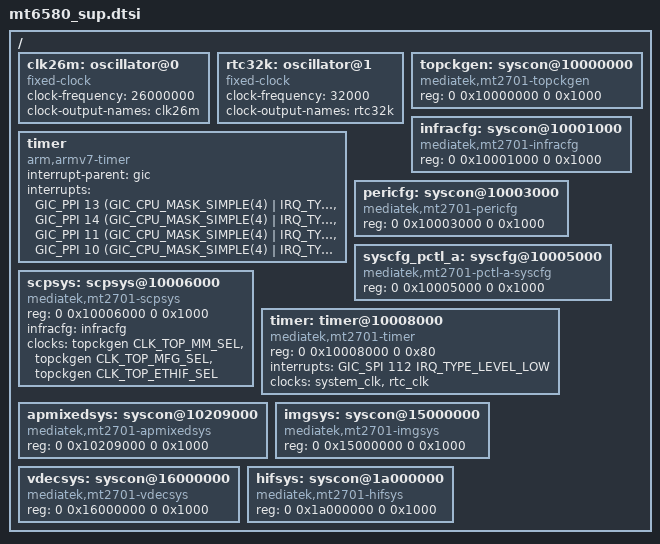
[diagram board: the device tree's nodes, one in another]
// SPDX-License-Identifier: GPL-2.0
/*
 * Copyright (c) 2015 MediaTek Inc.
 * Author: Erin.Lo <erin.lo@mediatek.com>
 *
 */

#include <dt-bindings/clock/mt2701-clk.h>
#include <dt-bindings/phy/phy.h>
#include <dt-bindings/power/mt2701-power.h>
#include <dt-bindings/interrupt-controller/irq.h>
#include <dt-bindings/interrupt-controller/arm-gic.h>
#include <dt-bindings/memory/mt2701-larb-port.h>
#include <dt-bindings/reset/mt2701-resets.h>
#include "mt2701-pinfunc.h"

/ {
	clk26m: oscillator@0 {
		compatible = "fixed-clock";
		#clock-cells = <0>;
		clock-frequency = <26000000>;
		clock-output-names = "clk26m";
	};

	rtc32k: oscillator@1 {
		compatible = "fixed-clock";
		#clock-cells = <0>;
		clock-frequency = <32000>;
		clock-output-names = "rtc32k";
	};

	timer {
		compatible = "arm,armv7-timer";
		interrupt-parent = <&gic>;
		interrupts = <GIC_PPI 13 (GIC_CPU_MASK_SIMPLE(4) | IRQ_TYPE_LEVEL_HIGH)>,
			     <GIC_PPI 14 (GIC_CPU_MASK_SIMPLE(4) | IRQ_TYPE_LEVEL_HIGH)>,
			     <GIC_PPI 11 (GIC_CPU_MASK_SIMPLE(4) | IRQ_TYPE_LEVEL_HIGH)>,
			     <GIC_PPI 10 (GIC_CPU_MASK_SIMPLE(4) | IRQ_TYPE_LEVEL_HIGH)>;
	};

	topckgen: syscon@10000000 {
		compatible = "mediatek,mt2701-topckgen", "syscon";
		reg = <0 0x10000000 0 0x1000>;
		#clock-cells = <1>;
	};

	infracfg: syscon@10001000 {
		compatible = "mediatek,mt2701-infracfg", "syscon";
		reg = <0 0x10001000 0 0x1000>;
		#clock-cells = <1>;
		#reset-cells = <1>;
	};

	pericfg: syscon@10003000 {
		compatible = "mediatek,mt2701-pericfg", "syscon";
		reg = <0 0x10003000 0 0x1000>;
		#clock-cells = <1>;
		#reset-cells = <1>;
	};

	syscfg_pctl_a: syscfg@10005000 {
		compatible = "mediatek,mt2701-pctl-a-syscfg", "syscon";
		reg = <0 0x10005000 0 0x1000>;
	};

	scpsys: scpsys@10006000 {
		compatible = "mediatek,mt2701-scpsys", "syscon";
		#power-domain-cells = <1>;
		reg = <0 0x10006000 0 0x1000>;
		infracfg = <&infracfg>;
		clocks = <&topckgen CLK_TOP_MM_SEL>,
			 <&topckgen CLK_TOP_MFG_SEL>,
			 <&topckgen CLK_TOP_ETHIF_SEL>;
		clock-names = "mm", "mfg", "ethif";
	};

	timer: timer@10008000 {
		compatible = "mediatek,mt2701-timer",
			     "mediatek,mt6577-timer";
		reg = <0 0x10008000 0 0x80>;
		interrupts = <GIC_SPI 112 IRQ_TYPE_LEVEL_LOW>;
		clocks = <&system_clk>, <&rtc_clk>;
		clock-names = "system-clk", "rtc-clk";
	};

	apmixedsys: syscon@10209000 {
		compatible = "mediatek,mt2701-apmixedsys", "syscon";
		reg = <0 0x10209000 0 0x1000>;
		#clock-cells = <1>;
	};

	imgsys: syscon@15000000 {
		compatible = "mediatek,mt2701-imgsys", "syscon";
		reg = <0 0x15000000 0 0x1000>;
		#clock-cells = <1>;
	};

	vdecsys: syscon@16000000 {
		compatible = "mediatek,mt2701-vdecsys", "syscon";
		reg = <0 0x16000000 0 0x1000>;
		#clock-cells = <1>;
	};

	hifsys: syscon@1a000000 {
		compatible = "mediatek,mt2701-hifsys", "syscon";
		reg = <0 0x1a000000 0 0x1000>;
		#clock-cells = <1>;
		#reset-cells = <1>;
	};
};
